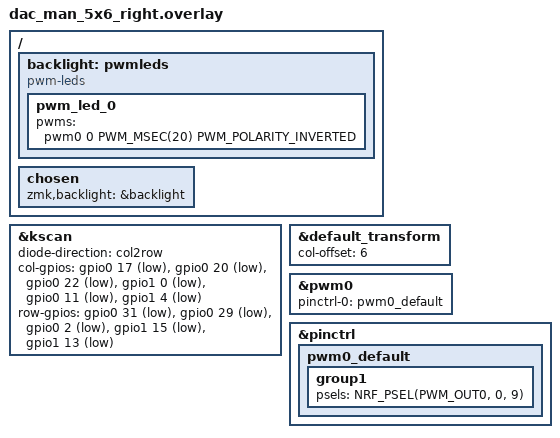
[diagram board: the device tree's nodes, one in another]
#include <dt-bindings/gpio/gpio.h>
#include "dac_man_5x6.dtsi"

&kscan {
    status = "okay";
    diode-direction = "col2row";
    col-gpios
        = <&gpio0 17 GPIO_ACTIVE_LOW>
        , <&gpio0 20 GPIO_ACTIVE_LOW>
        , <&gpio0 22 GPIO_ACTIVE_LOW>
        , <&gpio1 0  GPIO_ACTIVE_LOW>
        , <&gpio0 11 GPIO_ACTIVE_LOW>
        , <&gpio1 4  GPIO_ACTIVE_LOW>
        ;
    row-gpios
        = <&gpio0 31 (GPIO_ACTIVE_LOW | GPIO_PULL_UP)>
        , <&gpio0 29 (GPIO_ACTIVE_LOW | GPIO_PULL_UP)>
        , <&gpio0 2  (GPIO_ACTIVE_LOW | GPIO_PULL_UP)>
        , <&gpio1 15 (GPIO_ACTIVE_LOW | GPIO_PULL_UP)>
        , <&gpio1 13 (GPIO_ACTIVE_LOW | GPIO_PULL_UP)>
        ;
};

&default_transform {
    col-offset = <6>;
};

/ {
    backlight: pwmleds {
        compatible = "pwm-leds";
        pwm_led_0 {
            pwms = <&pwm0 0 PWM_MSEC(20) PWM_POLARITY_INVERTED>;
        };
    };
    
    chosen {
        zmk,backlight = &backlight;
    };
};

&pwm0 {
    status = "okay";
    pinctrl-0 = <&pwm0_default>;
    pinctrl-names = "default";
};

&pinctrl {
    pwm0_default: pwm0_default {
        group1 {
            psels = <NRF_PSEL(PWM_OUT0, 0, 9)>;
        };
    };
};
